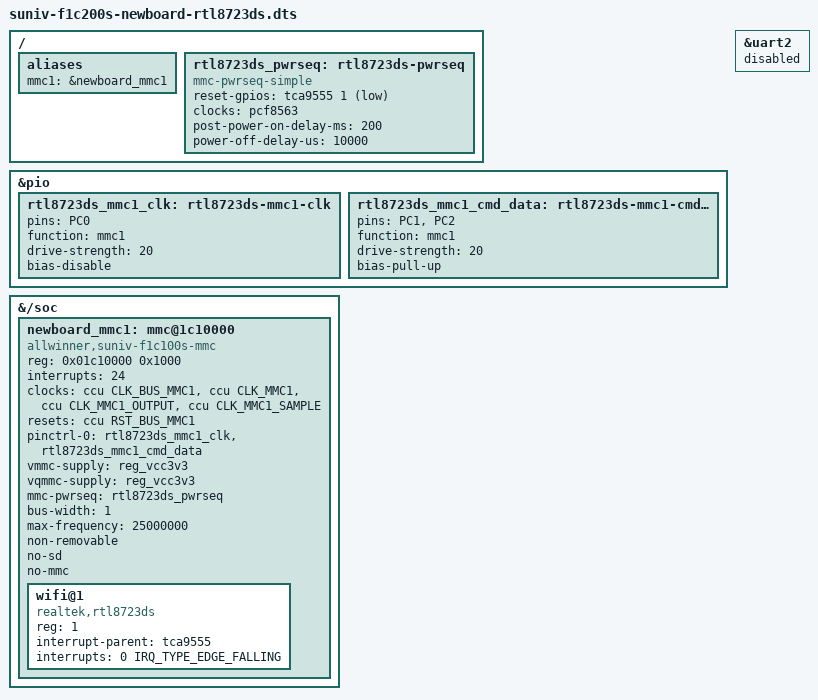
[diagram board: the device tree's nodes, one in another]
// SPDX-License-Identifier: (GPL-2.0+ OR X11)
#include "suniv-f1c100s-licheepi-nano-headphone.dts"

/ {
    aliases {
        mmc1 = &newboard_mmc1;
    };

    rtl8723ds_pwrseq: rtl8723ds-pwrseq {
        compatible = "mmc-pwrseq-simple";
        reset-gpios = <&tca9555 1 GPIO_ACTIVE_LOW>;
        clocks = <&pcf8563>;
        clock-names = "ext_clock";
        post-power-on-delay-ms = <200>;
        power-off-delay-us = <10000>;
    };
};

&pio {
    rtl8723ds_mmc1_clk: rtl8723ds-mmc1-clk {
        pins = "PC0";
        function = "mmc1";
        drive-strength = <20>;
        bias-disable;
    };

    rtl8723ds_mmc1_cmd_data: rtl8723ds-mmc1-cmd-data {
        pins = "PC1", "PC2";
        function = "mmc1";
        drive-strength = <20>;
        bias-pull-up;
    };
};

&{/soc} {
    newboard_mmc1: mmc@1c10000 {
        compatible = "allwinner,suniv-f1c100s-mmc",
                     "allwinner,sun7i-a20-mmc";
        reg = <0x01c10000 0x1000>;
        interrupts = <24>;
        clocks = <&ccu CLK_BUS_MMC1>, <&ccu CLK_MMC1>,
                 <&ccu CLK_MMC1_OUTPUT>, <&ccu CLK_MMC1_SAMPLE>;
        clock-names = "ahb", "mmc", "output", "sample";
        resets = <&ccu RST_BUS_MMC1>;
        reset-names = "ahb";
        pinctrl-names = "default";
        pinctrl-0 = <&rtl8723ds_mmc1_clk &rtl8723ds_mmc1_cmd_data>;
        vmmc-supply = <&reg_vcc3v3>;
        vqmmc-supply = <&reg_vcc3v3>;
        mmc-pwrseq = <&rtl8723ds_pwrseq>;
        bus-width = <1>;
        max-frequency = <25000000>;
        non-removable;
        no-sd;
        no-mmc;
        #address-cells = <1>;
        #size-cells = <0>;
        status = "okay";
        /* Normal operation uses SDIO in-band IRQ; no out-of-band wake enabled. */
        wifi@1 {
            compatible = "realtek,rtl8723ds";
            reg = <1>;
            interrupt-parent = <&tca9555>;
            interrupts = <0 IRQ_TYPE_EDGE_FALLING>;
        };
    };
};

/* UART2 Bluetooth remains disabled; the current kernel lacks HCIUART/serdev. */
&uart2 {
    status = "disabled";
};
